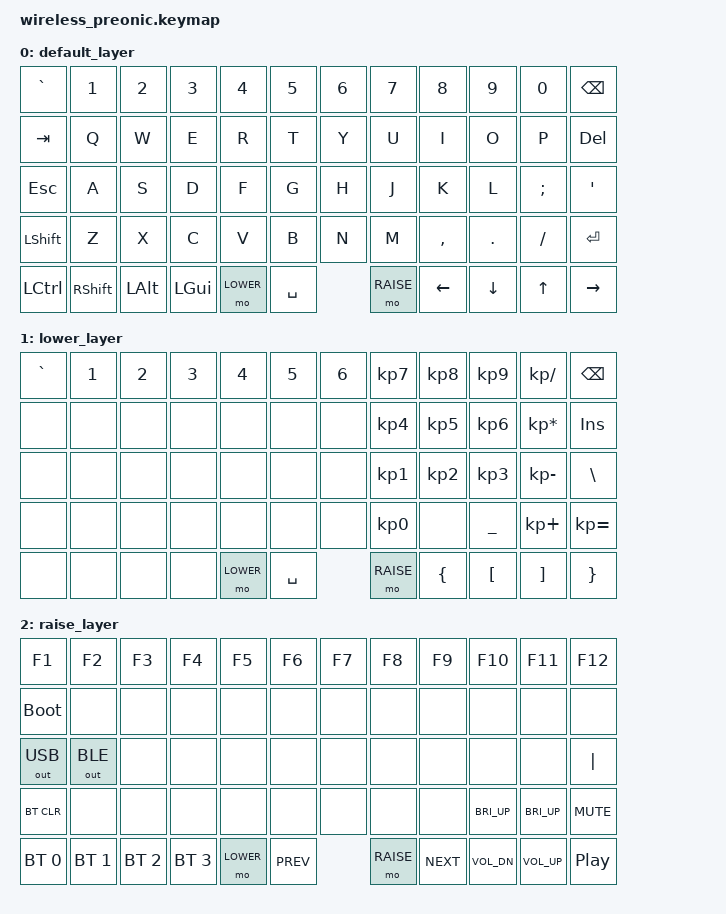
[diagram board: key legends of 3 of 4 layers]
#include <behaviors.dtsi>
#include <dt-bindings/zmk/keys.h>
#include <dt-bindings/zmk/bt.h>
#include <dt-bindings/zmk/outputs.h>

#define DEFAULT 0
#define LOWER   1
#define RAISE   2
#define ADJUST  3

/ {
    keymap {
        compatible = "zmk,keymap";

        default_layer {
            // ┌─────┬─────┬─────┬─────┬─────┬─────┬─────┬─────┬─────┬─────┬─────┬─────┐
            // │  `  │  1  │  2  │  3  │  4  │  5  │  6  │  7  │  8  │  9  │  0  │ BSPC│
            // ├─────┼─────┼─────┼─────┼─────┼─────┼─────┼─────┼─────┼─────┼─────┼─────┤
            // │ TAB │  Q  │  W  │  E  │  R  │  T  │  Y  │  U  │  I  │  O  │  P  │ DEL │
            // ├─────┼─────┼─────┼─────┼─────┼─────┼─────┼─────┼─────┼─────┼─────┼─────┤
            // │ ESC │  A  │  S  │  D  │  F  │  G  │  H  │  J  │  K  │  L  │  ;  │  '  │
            // ├─────┼─────┼─────┼─────┼─────┼─────┼─────┼─────┼─────┼─────┼─────┼─────┤
            // │SHIFT│  Z  │  X  │  C  │  V  │  B  │  N  │  M  │  ,  │  .  │  /  │ENTER│
            // ├─────┼─────┼─────┼─────┼─────┼─────┼─────┼─────┼─────┼─────┼─────┼─────┤
            // │CTRL │RSHFT│ OPTN│CMMND│LOWER│   SPACE   │RAISE│ LEFT│ DOWN│ UP  │RIGHT│
            // └─────┴─────┴─────┴─────┴─────┴─────┴─────┴─────┴─────┴─────┴─────┴─────┘
            bindings = <
                &kp GRAVE    &kp N1    &kp N2   &kp N3   &kp N4    &kp N5    &kp N6    &kp N7    &kp N8    &kp N9    &kp N0    &kp BSPC
                &kp TAB      &kp Q     &kp W    &kp E    &kp R     &kp T     &kp Y     &kp U     &kp I     &kp O     &kp P     &kp DEL
                &kp ESC      &kp A     &kp S    &kp D    &kp F     &kp G     &kp H     &kp J     &kp K     &kp L     &kp SEMI  &kp SQT
                &kp LSHFT    &kp Z     &kp X    &kp C    &kp V     &kp B     &kp N     &kp M     &kp COMMA &kp DOT   &kp FSLH  &kp RET
                &kp LCTRL    &kp RSHFT &kp LALT &kp LGUI &mo LOWER     &kp SPACE       &mo RAISE &kp LEFT  &kp DOWN  &kp UP    &kp RIGHT
            >;
        };
        lower_layer {
            // ┌─────┬─────┬─────┬─────┬─────┬─────┬─────┬─────┬─────┬─────┬─────┬─────┐
            // │  `  │  1  │  2  │  3  │  4  │  5  │  6  │  7  │  8  │  9  │  /  │ BSPC│
            // ├─────┼─────┼─────┼─────┼─────┼─────┼─────┼─────┼─────┼─────┼─────┼─────┤
            // │     │     │     │     │     │     │     │  4  │  5  │  6  │  *  │INSRT│
            // ├─────┼─────┼─────┼─────┼─────┼─────┼─────┼─────┼─────┼─────┼─────┼─────┤
            // │     │     │     │     │     │     │     │  1  │  2  │  3  │  -  │  \  │
            // ├─────┼─────┼─────┼─────┼─────┼─────┼─────┼─────┼─────┼─────┼─────┼─────┤
            // │     │     │     │     │     │     │     │  0  │     │  _  │  +  │  =  │
            // ├─────┼─────┼─────┼─────┼─────┼─────┼─────┼─────┼─────┼─────┼─────┼─────┤
            // │     │     │     │     │LOWER│   SPACE   │RAISE│  {  │  [  │  ]  │  }  │
            // └─────┴─────┴─────┴─────┴─────┴─────┴─────┴─────┴─────┴─────┴─────┴─────┘
            bindings = <
                &kp GRAVE &kp N1    &kp N2    &kp N3    &kp N4    &kp N5    &kp N6    &kp KP_N7    &kp KP_N8    &kp KP_N9    &kp KP_SLASH    &kp BSPC
                &none     &none     &none     &none     &none     &none     &none     &kp KP_N4    &kp KP_N5    &kp KP_N6    &kp KP_ASTERISK &kp INSERT
                &none     &none     &none     &none     &none     &none     &none     &kp KP_N1    &kp KP_N2    &kp KP_N3    &kp KP_MINUS    &kp BACKSLASH
                &none     &none     &none     &none     &none     &none     &none     &kp KP_N0    &none        &kp UNDER    &kp KP_PLUS     &kp KP_EQUAL
                &none     &none     &none     &none     &mo LOWER     &kp SPACE       &mo RAISE    &kp LBRC     &kp LBKT     &kp RBKT        &kp RBRC
            >;
        };

        raise_layer {
            // ┌─────┬─────┬─────┬─────┬─────┬─────┬─────┬─────┬─────┬─────┬─────┬─────┐
            // │  F1 │  F2 │  F3 │  F4 │  F5 │  F6 │  F7 │  F8 │  F9 │ F10 │ F11 │ F12 │
            // ├─────┼─────┼─────┼─────┼─────┼─────┼─────┼─────┼─────┼─────┼─────┼─────┤
            // │BTLDR│     │     │     │     │     │     │     │     │     │     │     │
            // ├─────┼─────┼─────┼─────┼─────┼─────┼─────┼─────┼─────┼─────┼─────┼─────┤
            // │ USB │ BLE │     │     │     │     │     │     │     │     │     │  |  │
            // ├─────┼─────┼─────┼─────┼─────┼─────┼─────┼─────┼─────┼─────┼─────┼─────┤
            // │BTCLR│     │     │     │     │     │     │     │     │ Bri-│ Bri+│ Mute│
            // ├─────┼─────┼─────┼─────┼─────┼─────┼─────┼─────┼─────┼─────┼─────┼─────┤
            // │ BT 0│ BT 1│ BT 2│ BT 3│LOWER│  Previous │RAISE│ Next│ Vol-│ Vol+│ Play│
            // └─────┴─────┴─────┴─────┴─────┴─────┴─────┴─────┴─────┴─────┴─────┴─────┘
            bindings = <
                &kp F1       &kp F2       &kp F3       &kp F4       &kp F5    &kp F6    &kp F7    &kp F8    &kp F9     &kp F10      &kp F11      &kp F12
                &bootloader  &none        &none        &none        &none     &none     &none     &none     &none      &none        &none        &none
                &out OUT_USB &out OUT_BLE &none        &none        &none     &none     &none     &none     &none      &none        &none        &kp PIPE
                &bt BT_CLR   &none        &none        &none        &none     &none     &none     &none     &none      &kp C_BRI_UP &kp C_BRI_UP &kp C_MUTE
                &bt BT_SEL 0 &bt BT_SEL 1 &bt BT_SEL 2 &bt BT_SEL 3 &mo LOWER     &kp C_PREV      &mo RAISE &kp C_NEXT &kp C_VOL_DN &kp C_VOL_UP &kp C_PP
            >;
        };

        adjust_layer {
            // ┌─────┬─────┬─────┬─────┬─────┬─────┬─────┬─────┬─────┬─────┬─────┬─────┐
            // │     │     │     │     │     │     │     │     │     │     │     │     │
            // ├─────┼─────┼─────┼─────┼─────┼─────┼─────┼─────┼─────┼─────┼─────┼─────┤
            // │     │     │     │     │     │     │     │     │     │     │     │     │
            // ├─────┼─────┼─────┼─────┼─────┼─────┼─────┼─────┼─────┼─────┼─────┼─────┤
            // │     │     │     │     │     │     │     │     │     │     │     │     │
            // ├─────┼─────┼─────┼─────┼─────┼─────┼─────┼─────┼─────┼─────┼─────┼─────┤
            // │     │     │     │     │     │     │     │     │     │     │     │     │
            // ├─────┼─────┼─────┼─────┼─────┼─────┼─────┼─────┼─────┼─────┼─────┼─────┤
            // │     │     │     │     │LOWER│   SPACE   │RAISE│     │     │     │     │
            // └─────┴─────┴─────┴─────┴─────┴─────┴─────┴─────┴─────┴─────┴─────┴─────┘
            bindings = <
                &none     &none     &none     &none     &none     &none     &none     &none     &none     &none     &none     &none
                &none     &none     &none     &none     &none     &none     &none     &none     &none     &none     &none     &none
                &none     &none     &none     &none     &none     &none     &none     &none     &none     &none     &none     &none
                &none     &none     &none     &none     &none     &none     &none     &none     &none     &none     &none     &none
                &none     &none     &none     &none     &mo LOWER &trans  &kp SPACE   &mo RAISE &none     &none     &none     &none
            >;
        };
    };
};
            // BLANK LAYOUT
            // ┌─────┬─────┬─────┬─────┬─────┬─────┬─────┬─────┬─────┬─────┬─────┬─────┐
            // │     │     │     │     │     │     │     │     │     │     │     │     │
            // ├─────┼─────┼─────┼─────┼─────┼─────┼─────┼─────┼─────┼─────┼─────┼─────┤
            // │     │     │     │     │     │     │     │     │     │     │     │     │
            // ├─────┼─────┼─────┼─────┼─────┼─────┼─────┼─────┼─────┼─────┼─────┼─────┤
            // │     │     │     │     │     │     │     │     │     │     │     │     │
            // ├─────┼─────┼─────┼─────┼─────┼─────┼─────┼─────┼─────┼─────┼─────┼─────┤
            // │     │     │     │     │     │     │     │     │     │     │     │     │
            // ├─────┼─────┼─────┼─────┼─────┼─────┼─────┼─────┼─────┼─────┼─────┼─────┤
            // │     │     │     │     │LOWER│   SPACE   │RAISE│     │     │     │     │
            // └─────┴─────┴─────┴─────┴─────┴─────┴─────┴─────┴─────┴─────┴─────┴─────┘
            //bindings = <
            //    &none     &none     &none     &none     &none     &none     &none     &none     &none     &none     &none     &none
            //    &none     &none     &none     &none     &none     &none     &none     &none     &none     &none     &none     &none
            //    &none     &none     &none     &none     &none     &none     &none     &none     &none     &none     &none     &none
            //    &none     &none     &none     &none     &none     &none     &none     &none     &none     &none     &none     &none
            //    &none     &none     &none     &none     &mo LOWER     &kp SPACE       &mo RAISE &none     &none     &none     &none
            //>;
